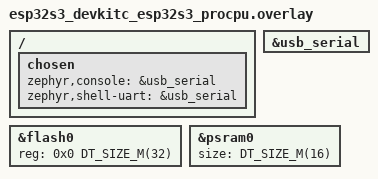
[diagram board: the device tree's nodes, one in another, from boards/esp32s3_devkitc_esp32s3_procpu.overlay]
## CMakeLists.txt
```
# SPDX-License-Identifier: Apache-2.0

cmake_minimum_required(VERSION 3.20.0)

include("${CMAKE_CURRENT_SOURCE_DIR}/../../cmake/deployment.cmake")
ros2_zephyr_compile_deployment("${CMAKE_CURRENT_SOURCE_DIR}/deployment.json")

if(BOARD MATCHES "^esp32")
  foreach(required_variable WIFI_SSID WIFI_PSK ROS_PEER_IP)
    if("$ENV{${required_variable}}" STREQUAL "")
      message(FATAL_ERROR "${required_variable} must be set for an ESP32 build")
    endif()
  endforeach()
  set(ros_peer_ip "$ENV{ROS_PEER_IP}")
  if(NOT ros_peer_ip MATCHES "^[0-9]+\\.[0-9]+\\.[0-9]+\\.[0-9]+$")
    message(FATAL_ERROR "ROS_PEER_IP must be an IPv4 address")
  endif()
  set(ROS2_ZEPHYR_CYCLONEDDS_URI
      "<CycloneDDS><Domain><General><AllowMulticast>false</AllowMulticast><MaxMessageSize>1400B</MaxMessageSize></General><Sizing><ReceiveBufferSize>8KiB</ReceiveBufferSize><ReceiveBufferChunkSize>4KiB</ReceiveBufferChunkSize></Sizing><Discovery><ParticipantIndex>0</ParticipantIndex><MaxAutoParticipantIndex>1</MaxAutoParticipantIndex><Peers><Peer Address='${ros_peer_ip}'/></Peers></Discovery><Threads><Thread Name='recv'><Scheduling><Class>timeshare</Class><Priority>8</Priority></Scheduling></Thread><Thread Name='tev'><Scheduling><Class>timeshare</Class><Priority>4</Priority></Scheduling></Thread><Thread Name='dq.user'><Scheduling><Class>timeshare</Class><Priority>4</Priority></Scheduling></Thread><Thread Name='dq.builtins'><Scheduling><Class>timeshare</Class><Priority>7</Priority></Scheduling></Thread><Thread Name='gc'><Scheduling><Class>timeshare</Class><Priority>4</Priority></Scheduling></Thread></Threads><Internal><MultipleReceiveThreads>false</MultipleReceiveThreads></Internal></Domain></CycloneDDS>"
      CACHE STRING "Cyclone DDS XML for static_control" FORCE
  )
endif()

list(APPEND ZEPHYR_EXTRA_MODULES "${CMAKE_CURRENT_SOURCE_DIR}/../..")
find_package(Zephyr REQUIRED HINTS $ENV{ZEPHYR_BASE})
project(ros2_zephyr_static_control C CXX)

if(CONFIG_WIFI AND CONFIG_NET_CONFIG_AUTO_INIT)
  message(FATAL_ERROR "static_control owns Wi-Fi association and DHCP readiness")
endif()

target_sources(app PRIVATE src/main.c src/control.c src/plant.c)
ros2_zephyr_add_generated_deployment(app)
target_include_directories(app PRIVATE src)
target_compile_options(app PRIVATE -Wall -Wextra -Werror)
option(ROS2_ZEPHYR_STATIC_CONTROL_TIMING_PROBE
       "Collect matched per-release and completion timing histograms" OFF)
if(ROS2_ZEPHYR_STATIC_CONTROL_TIMING_PROBE)
  target_compile_definitions(app PRIVATE STATIC_CONTROL_TIMING_PROBE=1)
endif()

if(CONFIG_WIFI)
  function(escape_c_string output input)
    string(REPLACE "\\" "\\\\" escaped "${input}")
    string(REPLACE "\"" "\\\"" escaped "${escaped}")
    string(REPLACE "\n" "\\n" escaped "${escaped}")
    string(REPLACE "\r" "\\r" escaped "${escaped}")
    set(${output} "${escaped}" PARENT_SCOPE)
  endfunction()

  escape_c_string(wifi_ssid_c "$ENV{WIFI_SSID}")
  escape_c_string(wifi_psk_c "$ENV{WIFI_PSK}")
  set(generated_directory "${CMAKE_CURRENT_BINARY_DIR}/generated")
  file(MAKE_DIRECTORY "${generated_directory}")
  configure_file(src/wifi_credentials.h.in "${generated_directory}/wifi_credentials.h" @ONLY)
  target_include_directories(app PRIVATE "${generated_directory}")
endif()
```

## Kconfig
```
# SPDX-License-Identifier: Apache-2.0

source "Kconfig.zephyr"

config STATIC_CONTROL_WIFI_RECONNECT_PROBE
	bool "Run the static-control Wi-Fi reconnect probe"
	depends on WIFI
	help
	  Disconnect the station once after startup, keep it offline for five
	  seconds, and reconnect with the configured credentials. This is a
	  hardware validation mode and must remain disabled in normal firmware.
```

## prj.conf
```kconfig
# SPDX-License-Identifier: Apache-2.0

CONFIG_ROS2_ZEPHYR=y
CONFIG_ROS2_ZEPHYR_DOMAIN_ID=95
CONFIG_ROS2_ZEPHYR_GRAPH_MAX_LOCAL_NODES=1
CONFIG_ROS2_ZEPHYR_GRAPH_MAX_ENDPOINTS_PER_NODE=2
CONFIG_ROS2_ZEPHYR_GRAPH_CACHE_MAX_PARTICIPANTS=3
CONFIG_ROS2_ZEPHYR_GRAPH_CACHE_MAX_NODES=6
CONFIG_ROS2_ZEPHYR_GRAPH_CACHE_MAX_ENDPOINTS=24

CONFIG_CPP=y
CONFIG_PICOLIBC=y
CONFIG_PICOLIBC_USE_MODULE=y
CONFIG_PICOLIBC_IO_LONG_LONG=y

CONFIG_MAIN_STACK_SIZE=16384
CONFIG_MAIN_THREAD_PRIORITY=4
CONFIG_HEAP_MEM_POOL_SIZE=131072
# Fixed endpoints peak below 86 KiB on native_sim. Keep a 3x arena margin.
CONFIG_COMMON_LIBC_MALLOC_ARENA_SIZE=262144
CONFIG_IDLE_STACK_SIZE=4096
CONFIG_SYSTEM_WORKQUEUE_STACK_SIZE=8192
CONFIG_THREAD_NAME=y
CONFIG_THREAD_MONITOR=y
CONFIG_THREAD_STACK_INFO=y
CONFIG_INIT_STACKS=y

CONFIG_POSIX_API=y
CONFIG_POSIX_THREADS=y
CONFIG_POSIX_THREAD_THREADS_MAX=10
CONFIG_MAX_PTHREAD_MUTEX_COUNT=300
CONFIG_MAX_PTHREAD_COND_COUNT=150
CONFIG_POSIX_THREAD_KEYS_MAX=32
CONFIG_POSIX_THREAD_ATTR_STACKSIZE=y
CONFIG_POSIX_THREADS_EXT=y
CONFIG_POSIX_THREAD_PRIORITY_SCHEDULING=y
CONFIG_STATIC_INIT_GNU=y

CONFIG_NETWORKING=y
CONFIG_NET_IPV4=y
CONFIG_NET_IPV6=n
CONFIG_NET_UDP=y
CONFIG_NET_SOCKETS=y
CONFIG_NET_CONFIG_SETTINGS=y
CONFIG_NET_CONFIG_NEED_IPV4=y
CONFIG_NET_CONFIG_MY_IPV4_ADDR="127.0.0.1"
CONFIG_NET_CONFIG_PEER_IPV4_ADDR="127.0.0.1"
CONFIG_NET_CONFIG_MY_IPV4_GW=""
CONFIG_NET_CONFIG_MY_IPV4_NETMASK="255.0.0.0"
CONFIG_NET_DRIVERS=y
CONFIG_NET_LOOPBACK=y
CONFIG_NET_L2_DUMMY=y
CONFIG_ETH_NATIVE_TAP=n
CONFIG_NET_PKT_RX_COUNT=32
CONFIG_NET_PKT_TX_COUNT=32
CONFIG_NET_BUF_RX_COUNT=128
CONFIG_NET_BUF_TX_COUNT=128
CONFIG_NET_BUF_DATA_SIZE=512
CONFIG_NET_CONTEXT_NET_PKT_POOL=y
CONFIG_NET_MAX_CONTEXTS=16
CONFIG_NET_SOCKETS_POLL_MAX=16
CONFIG_NET_IF_MCAST_IPV4_ADDR_COUNT=8

CONFIG_ENTROPY_GENERATOR=y
CONFIG_TEST_RANDOM_GENERATOR=y
CONFIG_LOG=y
CONFIG_LOG_MODE_IMMEDIATE=y
CONFIG_PRINTK=y
```

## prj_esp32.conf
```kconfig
# SPDX-License-Identifier: Apache-2.0

CONFIG_ROS2_ZEPHYR=y
CONFIG_ROS2_ZEPHYR_DOMAIN_ID=95
CONFIG_ROS2_ZEPHYR_CYCLONEDDS_THREAD_COUNT=5
CONFIG_ROS2_ZEPHYR_CYCLONEDDS_THREAD_STACK_SIZE=8192
CONFIG_ROS2_ZEPHYR_GRAPH_MAX_LOCAL_NODES=1
CONFIG_ROS2_ZEPHYR_GRAPH_MAX_ENDPOINTS_PER_NODE=2
CONFIG_ROS2_ZEPHYR_GRAPH_CACHE_MAX_PARTICIPANTS=3
CONFIG_ROS2_ZEPHYR_GRAPH_CACHE_MAX_NODES=6
CONFIG_ROS2_ZEPHYR_GRAPH_CACHE_MAX_ENDPOINTS=24

CONFIG_CPP=y
CONFIG_PICOLIBC=y
CONFIG_PICOLIBC_USE_MODULE=y
CONFIG_PICOLIBC_IO_LONG_LONG=y

CONFIG_MAIN_STACK_SIZE=12288
# The control thread runs at priority 3. ROS work must remain below it.
CONFIG_MAIN_THREAD_PRIORITY=4
CONFIG_HEAP_MEM_POOL_SIZE=56104
CONFIG_COMMON_LIBC_MALLOC_ARENA_SIZE=-1
CONFIG_IDLE_STACK_SIZE=1024
CONFIG_SYSTEM_WORKQUEUE_STACK_SIZE=4096
# Keep network and system work preemptible below the control thread at priority 3.
CONFIG_SYSTEM_WORKQUEUE_PRIORITY=5
CONFIG_SYS_HEAP_RUNTIME_STATS=y
CONFIG_SYS_HEAP_ARRAY_SIZE=8
CONFIG_MULTI_HEAP=y
CONFIG_THREAD_NAME=y
CONFIG_THREAD_MONITOR=y
CONFIG_THREAD_STACK_INFO=y
CONFIG_INIT_STACKS=y

CONFIG_POSIX_API=y
CONFIG_POSIX_THREADS=y
CONFIG_POSIX_THREAD_THREADS_MAX=8
CONFIG_MAX_PTHREAD_MUTEX_COUNT=256
CONFIG_MAX_PTHREAD_COND_COUNT=96
CONFIG_POSIX_THREAD_KEYS_MAX=8
CONFIG_POSIX_THREAD_ATTR_STACKSIZE=y
CONFIG_POSIX_THREADS_EXT=y
CONFIG_POSIX_THREAD_PRIORITY_SCHEDULING=y
CONFIG_POSIX_PRIORITY_SCHEDULING=y
CONFIG_STATIC_INIT_GNU=y

CONFIG_NETWORKING=y
CONFIG_NET_IPV4=y
CONFIG_NET_IPV6=n
CONFIG_NET_IPV4_IGMP=y
CONFIG_NET_IPV4_MTU=1500
CONFIG_NET_UDP=y
CONFIG_NET_SOCKETS=y
CONFIG_NET_HOSTNAME_ENABLE=y
CONFIG_NET_DHCPV4=y
CONFIG_NET_CONFIG_SETTINGS=y
CONFIG_NET_CONFIG_AUTO_INIT=n

CONFIG_WIFI=y
CONFIG_ESP32_WIFI_STA_AUTO_DHCPV4=y
CONFIG_ESP32_WIFI_STA_RECONNECT=y
CONFIG_ESP32_WIFI_STATIC_RX_BUFFER_NUM=2
CONFIG_ESP32_WIFI_DYNAMIC_RX_BUFFER_NUM=8
CONFIG_ESP32_WIFI_DYNAMIC_TX_BUFFER=y
CONFIG_ESP32_WIFI_DYNAMIC_TX_BUFFER_NUM=16
CONFIG_ESP32_WIFI_RX_BA_WIN=4

CONFIG_ENTROPY_GENERATOR=y
CONFIG_NET_PKT_RX_COUNT=8
CONFIG_NET_PKT_TX_COUNT=4
CONFIG_NET_BUF_RX_COUNT=32
CONFIG_NET_BUF_TX_COUNT=8
CONFIG_NET_BUF_DATA_SIZE=256
CONFIG_NET_CONTEXT_NET_PKT_POOL=y
CONFIG_NET_MAX_CONN=12
CONFIG_NET_MAX_CONTEXTS=12
CONFIG_NET_SOCKETS_POLL_MAX=8
CONFIG_NET_IF_MCAST_IPV4_ADDR_COUNT=4
CONFIG_NET_TC_THREAD_PREEMPTIVE=y
CONFIG_NET_TC_THREAD_PRIO_CUSTOM=y
CONFIG_NET_TC_RX_THREAD_BASE_PRIO=5

CONFIG_LOG=y
CONFIG_LOG_MODE_IMMEDIATE=y
CONFIG_PRINTK=y
```

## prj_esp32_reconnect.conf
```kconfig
# SPDX-License-Identifier: Apache-2.0

CONFIG_STATIC_CONTROL_WIFI_RECONNECT_PROBE=y
```

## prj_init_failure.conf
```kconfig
# SPDX-License-Identifier: Apache-2.0

CONFIG_ROS2_ZEPHYR_TEST_ROS_ALLOCATION_FAILURE_AT=10
```

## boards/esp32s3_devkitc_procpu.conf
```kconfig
# SPDX-License-Identifier: Apache-2.0

CONFIG_ESPTOOLPY_OCT_FLASH=y
CONFIG_ESPTOOLPY_FLASH_SAMPLE_MODE_STR=y

CONFIG_ESP_SPIRAM=y
CONFIG_SPIRAM_MODE_OCT=y
CONFIG_ESP_SPIRAM_HEAP_SIZE=1048576
```

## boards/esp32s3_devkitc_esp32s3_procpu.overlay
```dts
/* SPDX-License-Identifier: Apache-2.0 */

/ {
	chosen {
		zephyr,console = &usb_serial;
		zephyr,shell-uart = &usb_serial;
	};
};

&usb_serial {
	status = "okay";
};

&flash0 {
	reg = <0x0 DT_SIZE_M(32)>;
};

&psram0 {
	size = <DT_SIZE_M(16)>;
};
```

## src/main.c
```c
// SPDX-License-Identifier: Apache-2.0

#include <inttypes.h>
#include <stdbool.h>
#include <stdint.h>
#include <stdio.h>

#include <rcl/error_handling.h>
#include <rcl/rcl.h>
#include <rclc/executor.h>
#include <rclc/rclc.h>
#include <rcutils/logging.h>
#include <ros2_zephyr/allocator.h>
#include <zephyr/kernel.h>
#ifdef CONFIG_WIFI
#include <string.h>

#include <zephyr/net/net_event.h>
#include <zephyr/net/net_if.h>
#include <zephyr/net/net_ip.h>
#include <zephyr/net/net_mgmt.h>
#include <zephyr/net/wifi_mgmt.h>

#include "wifi_credentials.h"
#endif

#include "control.h"
#include "generated_ros_init.h"

enum {
  ROS_SPIN_TIMEOUT_MS = 20,
  TELEMETRY_PERIOD_MS = 100,
  REPORT_PERIOD_MS = 1000,
};

static uint32_t accepted_commands;
static uint32_t rejected_commands;

static bool check(rcl_ret_t result, const char *operation)
{
  if (result == RCL_RET_OK) {
    return true;
  }
  printf("STATIC_CONTROL_ERROR operation=%s code=%d detail=%s\n", operation, (int)result,
         rcl_get_error_string().str);
  rcl_reset_error();
  return false;
}

void command_callback(const void *message)
{
  const ros2_zephyr_test_msgs__msg__ControlCommand *ros_command = message;
  const struct static_control_command command = {
      .target = ros_command->target,
      .sequence = ros_command->sequence,
  };
  if (static_control_submit(&command, k_uptime_get())) {
    accepted_commands++;
  } else {
    rejected_commands++;
  }
}

#ifdef CONFIG_WIFI
static K_SEM_DEFINE(wifi_connected, 0, 1);
static K_SEM_DEFINE(wifi_disconnected, 0, 1);
static K_SEM_DEFINE(ipv4_ready, 0, 1);
static struct net_mgmt_event_callback wifi_callback;
static struct net_mgmt_event_callback ipv4_callback;

static struct wifi_connect_req_params wifi_connect_params(void)
{
  return (struct wifi_connect_req_params){
      .ssid = (const uint8_t *)ROS2_ZEPHYR_WIFI_SSID,
      .ssid_length = strlen(ROS2_ZEPHYR_WIFI_SSID),
      .psk = (const uint8_t *)ROS2_ZEPHYR_WIFI_PSK,
      .psk_length = strlen(ROS2_ZEPHYR_WIFI_PSK),
      .channel = WIFI_CHANNEL_ANY,
      .security = WIFI_SECURITY_TYPE_PSK,
  };
}

static void wifi_event_handler(struct net_mgmt_event_callback *callback, uint64_t event,
                               struct net_if *iface)
{
  (void)iface;
  const struct wifi_status *status = callback->info;
  if (status == NULL || status->status != 0) {
    const char *operation =
        event == NET_EVENT_WIFI_DISCONNECT_RESULT ? "wifi_disconnect" : "wifi_connect";
    printf("STATIC_CONTROL_ERROR operation=%s status=%d\n", operation,
           status != NULL ? status->status : -1);
    return;
  }
  if (event == NET_EVENT_WIFI_CONNECT_RESULT) {
    k_sem_give(&wifi_connected);
  } else if (event == NET_EVENT_WIFI_DISCONNECT_RESULT) {
    k_sem_give(&wifi_disconnected);
  }
}

static void ipv4_event_handler(struct net_mgmt_event_callback *callback, uint64_t event,
                               struct net_if *iface)
{
  (void)callback;
  (void)iface;
  if (event == NET_EVENT_IPV4_ADDR_ADD) {
    k_sem_give(&ipv4_ready);
  }
}

static bool connect_network(void)
{
  struct net_if *iface = net_if_get_default();
  struct wifi_connect_req_params params = wifi_connect_params();

  net_mgmt_init_event_callback(&wifi_callback, wifi_event_handler,
                               NET_EVENT_WIFI_CONNECT_RESULT |
                                   NET_EVENT_WIFI_DISCONNECT_RESULT);
  net_mgmt_add_event_callback(&wifi_callback);
  net_mgmt_init_event_callback(&ipv4_callback, ipv4_event_handler, NET_EVENT_IPV4_ADDR_ADD);
  net_mgmt_add_event_callback(&ipv4_callback);
  if (net_mgmt(NET_REQUEST_WIFI_CONNECT, iface, &params, sizeof(params)) != 0 ||
      k_sem_take(&wifi_connected, K_SECONDS(30)) != 0 ||
      k_sem_take(&ipv4_ready, K_SECONDS(30)) != 0) {
    printf("STATIC_CONTROL_ERROR operation=network_ready\n");
    return false;
  }

  struct wifi_ps_params power_save = {
      .enabled = WIFI_PS_DISABLED,
      .type = WIFI_PS_PARAM_STATE,
  };
  if (net_mgmt(NET_REQUEST_WIFI_PS, iface, &power_save, sizeof(power_save)) != 0) {
    printf("STATIC_CONTROL_ERROR operation=wifi_disable_power_save\n");
    return false;
  }
  const struct net_in_addr *address = net_if_ipv4_get_global_addr(iface, NET_ADDR_PREFERRED);
  char address_text[NET_IPV4_ADDR_LEN];
  if (address == NULL ||
      net_addr_ntop(NET_AF_INET, address, address_text, sizeof(address_text)) == NULL) {
    printf("STATIC_CONTROL_ERROR operation=wifi_ipv4_address\n");
    return false;
  }
  printf("STATIC_CONTROL_NETWORK_READY address=%s\n", address_text);
  return true;
}

#ifdef CONFIG_STATIC_CONTROL_WIFI_RECONNECT_PROBE
enum {
  WIFI_RECONNECT_PROBE_DELAY_MS = 10000,
  WIFI_RECONNECT_PROBE_OFFLINE_MS = 5000,
  WIFI_RECONNECT_PROBE_TIMEOUT_SECONDS = 30,
  WIFI_RECONNECT_PROBE_STACK_SIZE = 2048,
};

K_THREAD_STACK_DEFINE(wifi_reconnect_probe_stack, WIFI_RECONNECT_PROBE_STACK_SIZE);
static struct k_thread wifi_reconnect_probe_thread;

static void wifi_reconnect_probe(void *first, void *second, void *third)
{
  (void)first;
  (void)second;
  (void)third;
  struct net_if *iface = net_if_get_default();
  struct wifi_connect_req_params params = wifi_connect_params();

  k_sleep(K_MSEC(WIFI_RECONNECT_PROBE_DELAY_MS));
  printf("STATIC_CONTROL_WIFI_PROBE phase=disconnecting\n");
  if (net_mgmt(NET_REQUEST_WIFI_DISCONNECT, iface, NULL, 0) != 0 ||
      k_sem_take(&wifi_disconnected, K_SECONDS(WIFI_RECONNECT_PROBE_TIMEOUT_SECONDS)) != 0) {
    printf("STATIC_CONTROL_ERROR operation=wifi_probe_disconnect\n");
    return;
  }
  printf("STATIC_CONTROL_WIFI_PROBE phase=disconnected\n");

  k_sleep(K_MSEC(WIFI_RECONNECT_PROBE_OFFLINE_MS));
  if (net_mgmt(NET_REQUEST_WIFI_CONNECT, iface, &params, sizeof(params)) != 0 ||
      k_sem_take(&wifi_connected, K_SECONDS(WIFI_RECONNECT_PROBE_TIMEOUT_SECONDS)) != 0 ||
      k_sem_take(&ipv4_ready, K_SECONDS(WIFI_RECONNECT_PROBE_TIMEOUT_SECONDS)) != 0) {
    printf("STATIC_CONTROL_ERROR operation=wifi_probe_reconnect\n");
    return;
  }
  printf("STATIC_CONTROL_WIFI_PROBE phase=reconnected\n");
}

static void start_wifi_reconnect_probe(void)
{
  (void)k_thread_create(&wifi_reconnect_probe_thread, wifi_reconnect_probe_stack,
                        K_THREAD_STACK_SIZEOF(wifi_reconnect_probe_stack), wifi_reconnect_probe,
                        NULL, NULL, NULL, 5, 0, K_NO_WAIT);
  k_thread_name_set(&wifi_reconnect_probe_thread, "wifi_reconnect_probe");
}
#endif
#else
static bool connect_network(void) { return true; }
#endif

int main(void)
{
  printf("STATIC_CONTROL_START board=%s period_ms=10 expiry_ms=250 deadline_ms=10\n",
         CONFIG_BOARD_TARGET);
  if (!connect_network()) {
    return 1;
  }

  rcl_allocator_t allocator = {
      .allocate = ros2_zephyr_allocate,
      .deallocate = ros2_zephyr_deallocate,
      .reallocate = ros2_zephyr_reallocate,
      .zero_allocate = ros2_zephyr_zero_allocate,
      .state = ros2_zephyr_allocator_state(ROS2_ZEPHYR_ALLOCATION_ROS),
  };
  rclc_support_t support = {0};
  ros2z_deployment_context_t deployment = {0};
  bool support_initialized = false;
  bool deployment_initialized = false;
  bool control_started = false;
  int result = 1;

  if (!check(rclc_support_init(&support, 0, NULL, &allocator), "support_init")) {
    goto cleanup;
  }
  support_initialized = true;
  if (!check(ros2z_deployment_init(&deployment, &support, &allocator), "deployment_init")) {
    goto cleanup;
  }
  deployment_initialized = true;
  if (!static_control_start()) {
    printf("STATIC_CONTROL_ERROR operation=control_start\n");
    goto cleanup;
  }
  control_started = true;

  const ros2_zephyr_allocation_metrics_t ros_prepared =
      ros2_zephyr_allocation_metrics(ROS2_ZEPHYR_ALLOCATION_ROS);
  const ros2_zephyr_allocation_metrics_t middleware_prepared =
      ros2_zephyr_allocation_metrics(ROS2_ZEPHYR_ALLOCATION_MIDDLEWARE);
  printf("STATIC_CONTROL_READY ros_alloc_calls=%zu middleware_alloc_calls=%zu\n",
         ros_prepared.calls, middleware_prepared.calls);
#ifdef CONFIG_STATIC_CONTROL_WIFI_RECONNECT_PROBE
  start_wifi_reconnect_probe();
#endif

  int64_t next_telemetry_ms = k_uptime_get();
  int64_t next_report_ms = next_telemetry_ms + REPORT_PERIOD_MS;
  uint8_t previous_status = UINT8_MAX;
  for (;;) {
    const rcl_ret_t spin =
        rclc_executor_spin_some(&deployment.executor, RCL_MS_TO_NS(ROS_SPIN_TIMEOUT_MS));
    if (spin != RCL_RET_OK && spin != RCL_RET_TIMEOUT) {
      (void)check(spin, "spin_some");
      k_sleep(K_MSEC(ROS_SPIN_TIMEOUT_MS));
    }

    const int64_t now_ms = k_uptime_get();
    if (now_ms >= next_telemetry_ms) {
      const struct static_control_state state = static_control_read_state();
      ros2_zephyr_test_msgs__msg__ControlState ros_state = {
          .position = state.position,
          .velocity = state.velocity,
          .effort = state.effort,
          .command_sequence = state.command_sequence,
          .control_cycles = state.control_cycles,
          .skipped_releases = state.skipped_releases,
          .status = state.status,
      };
      const rcl_ret_t publish = rcl_publish(&deployment.publisher_state, &ros_state, NULL);
      if (publish != RCL_RET_OK) {
        (void)check(publish, "publish_state");
      }
      next_telemetry_ms = now_ms + TELEMETRY_PERIOD_MS;
      if (state.status != previous_status) {
        printf("STATIC_CONTROL_STATUS status=%u sequence=%" PRIu32 " cycles=%" PRIu32
               " skipped=%" PRIu32 "\n",
               state.status, state.command_sequence, state.control_cycles, state.skipped_releases);
        previous_status = state.status;
      }
    }
    if (now_ms >= next_report_ms) {
      const struct static_control_state state = static_control_read_state();
      const ros2_zephyr_allocation_metrics_t ros_now =
          ros2_zephyr_allocation_metrics(ROS2_ZEPHYR_ALLOCATION_ROS);
      const ros2_zephyr_allocation_metrics_t middleware_now =
          ros2_zephyr_allocation_metrics(ROS2_ZEPHYR_ALLOCATION_MIDDLEWARE);
      size_t control_stack_unused = 0U;
      const bool stack_measured = static_control_stack_space(&control_stack_unused);
      printf("STATIC_CONTROL_METRICS accepted=%" PRIu32 " rejected=%" PRIu32
             " ros_steady_alloc_calls=%zu middleware_steady_alloc_calls=%zu"
             " ros_high_water=%zu middleware_high_water=%zu"
             " max_lateness_us=%" PRIu32 " skipped=%" PRIu32 " control_stack_unused=%s",
             accepted_commands, rejected_commands, ros_now.calls - ros_prepared.calls,
             middleware_now.calls - middleware_prepared.calls, ros_now.high_water_bytes,
             middleware_now.high_water_bytes, state.max_release_lateness_us,
             state.skipped_releases,
             stack_measured ? "measured" : "unavailable");
      if (stack_measured) {
        printf(" unused_bytes=%zu", control_stack_unused);
      }
      printf("\n");
#ifdef STATIC_CONTROL_TIMING_PROBE
      const struct static_control_timing timing = static_control_timing_read();
      printf("STATIC_CONTROL_TIMING samples=%" PRIu32
             " release_p50_us=%" PRIu32 " release_p95_us=%" PRIu32
             " release_p99_us=%" PRIu32 " release_max_us=%" PRIu32
             " completion_p50_us=%" PRIu32 " completion_p95_us=%" PRIu32
             " completion_p99_us=%" PRIu32 " completion_max_us=%" PRIu32 "\n",
             timing.samples, timing.release_p50_us, timing.release_p95_us,
             timing.release_p99_us, timing.release_max_us,
             timing.completion_p50_us, timing.completion_p95_us,
             timing.completion_p99_us, timing.completion_max_us);
#endif
      next_report_ms = now_ms + REPORT_PERIOD_MS;
    }
  }

cleanup:
  if (control_started) {
    static_control_stop();
  }
  if (deployment_initialized && ros2z_deployment_fini(&deployment) != RCL_RET_OK) {
    result = 1;
  }
  if (support_initialized && rclc_support_fini(&support) != RCL_RET_OK) {
    result = 1;
  }
  if (rcutils_logging_shutdown() != RCUTILS_RET_OK) {
    result = 1;
  }
  const ros2_zephyr_allocation_metrics_t ros_final =
      ros2_zephyr_allocation_metrics(ROS2_ZEPHYR_ALLOCATION_ROS);
  const ros2_zephyr_allocation_metrics_t middleware_final =
      ros2_zephyr_allocation_metrics(ROS2_ZEPHYR_ALLOCATION_MIDDLEWARE);
  printf("STATIC_CONTROL_CLEANUP result=%d ros_live=%zu middleware_live=%zu\n", result,
         ros_final.live_bytes, middleware_final.live_bytes);
  return result;
}
```

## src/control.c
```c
// SPDX-License-Identifier: Apache-2.0

#include "control.h"

#include <math.h>
#include <stddef.h>
#include <string.h>

#include <zephyr/kernel.h>
#include <zephyr/spinlock.h>
#include <zephyr/sys/atomic.h>
#include <zephyr/sys/util.h>

#include "plant.h"

enum {
  CONTROL_PERIOD_MS = 10,
  CONTROL_DEADLINE_MS = 10,
  COMMAND_EXPIRY_MS = 250,
  CONTROL_THREAD_PRIORITY = 3,
  CONTROL_STACK_SIZE = 2048,
};

BUILD_ASSERT(CONFIG_MAIN_THREAD_PRIORITY > CONTROL_THREAD_PRIORITY,
             "the ROS-owning main thread must not preempt the control thread");

struct command_snapshot {
  struct k_spinlock lock;
  struct static_control_command value;
  int64_t receipt_ms;
  bool valid;
};

struct state_snapshot {
  struct k_spinlock lock;
  struct static_control_state value;
};

static struct command_snapshot command_snapshot;
static struct state_snapshot state_snapshot;
static struct k_timer release_timer;
static atomic_t stop_requested;
static atomic_t running;
#ifdef STATIC_CONTROL_TEST
static atomic_t test_delay_ms;
#endif
K_THREAD_STACK_DEFINE(control_stack, CONTROL_STACK_SIZE);
static struct k_thread control_thread;
static k_tid_t control_thread_id;

#ifdef STATIC_CONTROL_TIMING_PROBE
enum { TIMING_BUCKET_US = 100, TIMING_BUCKET_COUNT = 102 };
static struct {
  struct k_spinlock lock;
  uint32_t last_release_cycles;
  uint32_t samples;
  uint32_t release_hist[TIMING_BUCKET_COUNT];
  uint32_t completion_hist[TIMING_BUCKET_COUNT];
  uint32_t release_max_us;
  uint32_t completion_max_us;
} timing;

static void release_expiry(struct k_timer *timer)
{
  ARG_UNUSED(timer);
  const uint32_t cycles = k_cycle_get_32();
  k_spinlock_key_t key = k_spin_lock(&timing.lock);
  timing.last_release_cycles = cycles;
  k_spin_unlock(&timing.lock, key);
}

static uint32_t timing_release_cycles(void)
{
  k_spinlock_key_t key = k_spin_lock(&timing.lock);
  const uint32_t cycles = timing.last_release_cycles;
  k_spin_unlock(&timing.lock, key);
  return cycles;
}

static void timing_record(uint32_t release_cycles, uint32_t start_cycles,
                          uint32_t completion_cycles)
{
  /* Each difference spans at most one 10 ms period, well below 2^32 cycles.
   * Unsigned subtraction remains correct across a counter wrap.
   */
  const uint64_t release_us_64 =
      k_cyc_to_us_floor64((uint32_t)(start_cycles - release_cycles));
  const uint64_t completion_us_64 =
      k_cyc_to_us_floor64((uint32_t)(completion_cycles - release_cycles));
  const uint32_t release_us = (uint32_t)MIN(release_us_64, UINT32_MAX);
  const uint32_t completion_late_us =
      (uint32_t)MIN(completion_us_64 > CONTROL_DEADLINE_MS * 1000U
                        ? completion_us_64 - CONTROL_DEADLINE_MS * 1000U : 0U,
                    UINT32_MAX);
  const size_t release_bucket = MIN(release_us / TIMING_BUCKET_US,
                                    TIMING_BUCKET_COUNT - 1U);
  const size_t completion_bucket = MIN(completion_late_us / TIMING_BUCKET_US,
                                       TIMING_BUCKET_COUNT - 1U);
  k_spinlock_key_t key = k_spin_lock(&timing.lock);
  timing.samples++;
  timing.release_hist[release_bucket]++;
  timing.completion_hist[completion_bucket]++;
  timing.release_max_us = MAX(timing.release_max_us, release_us);
  timing.completion_max_us = MAX(timing.completion_max_us, completion_late_us);
  k_spin_unlock(&timing.lock, key);
}

static uint32_t timing_percentile(const uint32_t *hist, uint32_t samples, uint32_t percentile)
{
  if (samples == 0U) {
    return 0U;
  }
  const uint32_t rank = (samples * percentile + 99U) / 100U;
  uint32_t cumulative = 0U;
  for (size_t bucket = 0; bucket < TIMING_BUCKET_COUNT; bucket++) {
    cumulative += hist[bucket];
    if (cumulative >= rank) {
      return (uint32_t)(bucket + 1U) * TIMING_BUCKET_US;
    }
  }
  return TIMING_BUCKET_COUNT * TIMING_BUCKET_US;
}

struct static_control_timing static_control_timing_read(void)
{
  uint32_t release_hist[TIMING_BUCKET_COUNT];
  uint32_t completion_hist[TIMING_BUCKET_COUNT];
  struct static_control_timing result;
  k_spinlock_key_t key = k_spin_lock(&timing.lock);
  result.samples = timing.samples;
  result.release_max_us = timing.release_max_us;
  result.completion_max_us = timing.completion_max_us;
  memcpy(release_hist, timing.release_hist, sizeof(release_hist));
  memcpy(completion_hist, timing.completion_hist, sizeof(completion_hist));
  k_spin_unlock(&timing.lock, key);
  result.release_p50_us = timing_percentile(release_hist, result.samples, 50U);
  result.release_p95_us = timing_percentile(release_hist, result.samples, 95U);
  result.release_p99_us = timing_percentile(release_hist, result.samples, 99U);
  result.completion_p50_us = timing_percentile(completion_hist, result.samples, 50U);
  result.completion_p95_us = timing_percentile(completion_hist, result.samples, 95U);
  result.completion_p99_us = timing_percentile(completion_hist, result.samples, 99U);
  return result;
}
#endif

static void publish_state(const struct static_control_state *state)
{
  k_spinlock_key_t key = k_spin_lock(&state_snapshot.lock);
  state_snapshot.value = *state;
  k_spin_unlock(&state_snapshot.lock, key);
}

static void read_command(struct static_control_command *command, int64_t *receipt_ms, bool *valid)
{
  k_spinlock_key_t key = k_spin_lock(&command_snapshot.lock);
  *command = command_snapshot.value;
  *receipt_ms = command_snapshot.receipt_ms;
  *valid = command_snapshot.valid;
  k_spin_unlock(&command_snapshot.lock, key);
}

static void control_entry(void *first, void *second, void *third)
{
  ARG_UNUSED(first);
  ARG_UNUSED(second);
  ARG_UNUSED(third);

  struct static_control_plant plant;
  struct static_control_state state = {.status = STATIC_CONTROL_DISABLED};
  int64_t scheduled_release_ms = k_uptime_get() + CONTROL_PERIOD_MS;
  bool faulted = false;
  static_control_plant_init(&plant);
  publish_state(&state);
  k_timer_start(&release_timer, K_MSEC(CONTROL_PERIOD_MS), K_MSEC(CONTROL_PERIOD_MS));

  while (atomic_get(&stop_requested) == 0) {
    const uint32_t releases = k_timer_status_sync(&release_timer);
    if (atomic_get(&stop_requested) != 0) {
      break;
    }
#ifdef STATIC_CONTROL_TIMING_PROBE
    const uint32_t release_cycles = timing_release_cycles();
    const uint32_t start_cycles = k_cycle_get_32();
#endif

    const int64_t start_ms = k_uptime_get();
#ifdef STATIC_CONTROL_TEST
    const atomic_val_t delay_ms = atomic_set(&test_delay_ms, 0);
    if (delay_ms > 0) {
      k_sleep(K_MSEC(delay_ms));
    }
#endif
    const int64_t lateness_ms = start_ms - scheduled_release_ms;
    if (lateness_ms > 0) {
      state.max_release_lateness_us =
          MAX(state.max_release_lateness_us, (uint32_t)lateness_ms * 1000U);
    }
    if (releases > 1U) {
      state.skipped_releases += releases - 1U;
      faulted = true;
    }
    scheduled_release_ms += (int64_t)releases * CONTROL_PERIOD_MS;

    struct static_control_command command = {0};
    int64_t receipt_ms = 0;
    bool command_valid = false;
    read_command(&command, &receipt_ms, &command_valid);
    const bool command_fresh =
        command_valid && start_ms >= receipt_ms && start_ms - receipt_ms <= COMMAND_EXPIRY_MS;
    if (start_ms > scheduled_release_ms) {
      faulted = true;
    }

    struct static_control_plant_output output;
    static_control_plant_step(&plant, command.target, CONTROL_PERIOD_MS / 1000.0F,
                              command_fresh && !faulted, &output);
    const int64_t completion_ms = k_uptime_get();
#ifdef STATIC_CONTROL_TIMING_PROBE
    if (releases == 1U) {
      timing_record(release_cycles, start_cycles, k_cycle_get_32());
    }
#endif
    if (completion_ms > scheduled_release_ms - CONTROL_PERIOD_MS + CONTROL_DEADLINE_MS) {
      faulted = true;
      output.effort = 0.0F;
    }

    state.position = output.position;
    state.velocity = output.velocity;
    state.effort = faulted ? 0.0F : output.effort;
    state.command_sequence = command.sequence;
    state.control_cycles++;
    state.status = faulted          ? STATIC_CONTROL_FAULT
                   : !command_valid ? STATIC_CONTROL_DISABLED
                   : !command_fresh ? STATIC_CONTROL_STALE
                                    : STATIC_CONTROL_ACTIVE;
    publish_state(&state);
  }

  k_timer_stop(&release_timer);
  atomic_clear(&running);
}

bool static_control_start(void)
{
  if (!atomic_cas(&running, 0, 1)) {
    return false;
  }
  atomic_clear(&stop_requested);
#ifdef STATIC_CONTROL_TEST
  atomic_clear(&test_delay_ms);
#endif
  command_snapshot.valid = false;
  state_snapshot.value = (struct static_control_state){.status = STATIC_CONTROL_DISABLED};
#ifdef STATIC_CONTROL_TIMING_PROBE
  memset(&timing, 0, sizeof(timing));
  k_timer_init(&release_timer, release_expiry, NULL);
#else
  k_timer_init(&release_timer, NULL, NULL);
#endif
  control_thread_id =
      k_thread_create(&control_thread, control_stack, K_THREAD_STACK_SIZEOF(control_stack),
                      control_entry, NULL, NULL, NULL, CONTROL_THREAD_PRIORITY, 0, K_NO_WAIT);
  k_thread_name_set(control_thread_id, "static-control");
  return true;
}

void static_control_stop(void)
{
  if (atomic_get(&running) == 0) {
    return;
  }
  atomic_set(&stop_requested, 1);
  k_timer_start(&release_timer, K_TICKS(1), K_NO_WAIT);
  (void)k_thread_join(control_thread_id, K_FOREVER);
}

bool static_control_submit(const struct static_control_command *command, int64_t receipt_ms)
{
  if (command == NULL || !isfinite(command->target) || command->target < -1.0F ||
      command->target > 1.0F || receipt_ms < 0) {
    return false;
  }
  k_spinlock_key_t key = k_spin_lock(&command_snapshot.lock);
  command_snapshot.value = *command;
  command_snapshot.receipt_ms = receipt_ms;
  command_snapshot.valid = true;
  k_spin_unlock(&command_snapshot.lock, key);
  return true;
}

struct static_control_state static_control_read_state(void)
{
  k_spinlock_key_t key = k_spin_lock(&state_snapshot.lock);
  const struct static_control_state state = state_snapshot.value;
  k_spin_unlock(&state_snapshot.lock, key);
  return state;
}

bool static_control_stack_space(size_t *unused_bytes)
{
  return unused_bytes != NULL && control_thread_id != NULL &&
         k_thread_stack_space_get(control_thread_id, unused_bytes) == 0;
}

#ifdef STATIC_CONTROL_TEST
void static_control_test_delay_next_cycle(uint32_t delay_ms)
{
  atomic_set(&test_delay_ms, (atomic_val_t)delay_ms);
}
#endif
```

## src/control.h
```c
// SPDX-License-Identifier: Apache-2.0

#ifndef ROS2_ZEPHYR_STATIC_CONTROL_CONTROL_H_
#define ROS2_ZEPHYR_STATIC_CONTROL_CONTROL_H_

#include <stdbool.h>
#include <stddef.h>
#include <stdint.h>

enum static_control_status {
  STATIC_CONTROL_DISABLED = 0,
  STATIC_CONTROL_ACTIVE = 1,
  STATIC_CONTROL_STALE = 2,
  STATIC_CONTROL_FAULT = 3,
};

struct static_control_command {
  float target;
  uint32_t sequence;
};

struct static_control_state {
  float position;
  float velocity;
  float effort;
  uint32_t command_sequence;
  uint32_t control_cycles;
  uint32_t skipped_releases;
  uint32_t max_release_lateness_us;
  uint8_t status;
};

bool static_control_start(void);
void static_control_stop(void);
bool static_control_submit(const struct static_control_command *command, int64_t receipt_ms);
struct static_control_state static_control_read_state(void);
bool static_control_stack_space(size_t *unused_bytes);

#ifdef STATIC_CONTROL_TIMING_PROBE
struct static_control_timing {
  uint32_t samples;
  uint32_t release_p50_us;
  uint32_t release_p95_us;
  uint32_t release_p99_us;
  uint32_t release_max_us;
  uint32_t completion_p50_us;
  uint32_t completion_p95_us;
  uint32_t completion_p99_us;
  uint32_t completion_max_us;
};
struct static_control_timing static_control_timing_read(void);
#endif

#ifdef STATIC_CONTROL_TEST
void static_control_test_delay_next_cycle(uint32_t delay_ms);
#endif

#endif
```

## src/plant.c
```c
// SPDX-License-Identifier: Apache-2.0

#include "plant.h"

enum {
  PROPORTIONAL_GAIN = 4,
  DAMPING_GAIN = 1,
};

static float clamp(float value, float lower, float upper)
{
  if (value < lower) {
    return lower;
  }
  if (value > upper) {
    return upper;
  }
  return value;
}

void static_control_plant_init(struct static_control_plant *plant)
{
  plant->position = 0.0F;
  plant->velocity = 0.0F;
}

void static_control_plant_step(struct static_control_plant *plant, float target,
                               float period_seconds, bool output_enabled,
                               struct static_control_plant_output *output)
{
  float effort = 0.0F;
  if (output_enabled) {
    effort = clamp(PROPORTIONAL_GAIN * (target - plant->position) - DAMPING_GAIN * plant->velocity,
                   -1.0F, 1.0F);
  }

  const float acceleration = effort - 0.2F * plant->velocity;
  plant->velocity += acceleration * period_seconds;
  plant->position += plant->velocity * period_seconds;

  output->position = plant->position;
  output->velocity = plant->velocity;
  output->effort = effort;
}
```

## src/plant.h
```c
// SPDX-License-Identifier: Apache-2.0

#ifndef ROS2_ZEPHYR_STATIC_CONTROL_PLANT_H_
#define ROS2_ZEPHYR_STATIC_CONTROL_PLANT_H_

#include <stdbool.h>

struct static_control_plant {
  float position;
  float velocity;
};

struct static_control_plant_output {
  float position;
  float velocity;
  float effort;
};

void static_control_plant_init(struct static_control_plant *plant);

void static_control_plant_step(struct static_control_plant *plant, float target,
                               float period_seconds, bool output_enabled,
                               struct static_control_plant_output *output);

#endif
```
